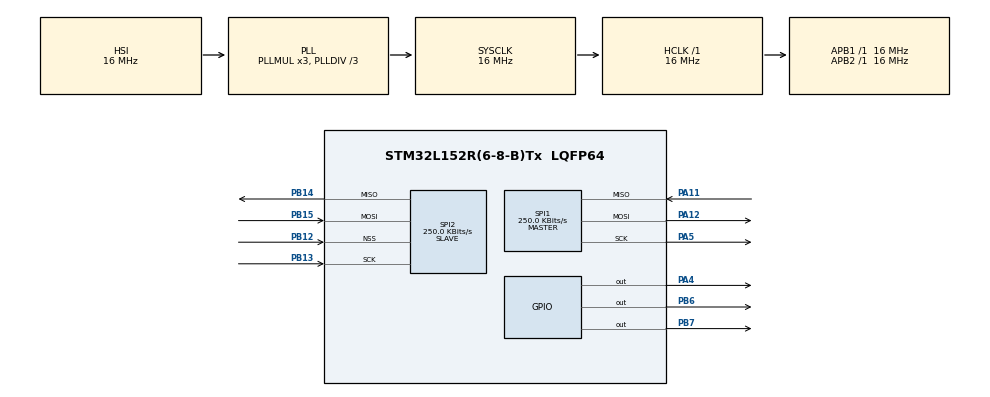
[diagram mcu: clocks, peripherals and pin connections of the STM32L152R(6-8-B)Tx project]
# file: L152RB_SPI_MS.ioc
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Dma.Request0=SPI2_RX
Dma.SPI2_RX.0.Direction=DMA_PERIPH_TO_MEMORY
Dma.SPI2_RX.0.Instance=DMA1_Channel4
Dma.SPI2_RX.0.MemDataAlignment=DMA_MDATAALIGN_BYTE
Dma.SPI2_RX.0.MemInc=DMA_MINC_ENABLE
Dma.SPI2_RX.0.Mode=DMA_CIRCULAR
Dma.SPI2_RX.0.PeriphDataAlignment=DMA_PDATAALIGN_BYTE
Dma.SPI2_RX.0.PeriphInc=DMA_PINC_DISABLE
Dma.SPI2_RX.0.Priority=DMA_PRIORITY_LOW
Mcu.Family=STM32L1
Mcu.Name=STM32L152R(6-8-B)Tx
Mcu.Package=LQFP64
NVIC.DMA1_Channel4_IRQn=true\:0\:0\:false\:false\:true\:false\:true
NVIC.PriorityGroup=NVIC_PRIORITYGROUP_4
NVIC.SPI1_IRQn=true\:0\:0\:false\:false\:true\:true\:true
NVIC.SPI2_IRQn=true\:0\:0\:false\:false\:true\:true\:true
PA11.Mode=Full_Duplex_Master
PA11.Signal=SPI1_MISO
PA12.Mode=Full_Duplex_Master
PA12.Signal=SPI1_MOSI
PA4.GPIO_Speed=GPIO_SPEED_FREQ_VERY_HIGH
PA4.PinState=GPIO_PIN_SET
PA4.Signal=GPIO_Output
PA5.Mode=Full_Duplex_Master
PA5.Signal=SPI1_SCK
PB12.Mode=NSS_Signal_Hard_Input
PB12.Signal=SPI2_NSS
PB13.Mode=Full_Duplex_Slave
PB13.Signal=SPI2_SCK
PB14.Mode=Full_Duplex_Slave
PB14.Signal=SPI2_MISO
PB15.Mode=Full_Duplex_Slave
PB15.Signal=SPI2_MOSI
PB6.PinState=GPIO_PIN_SET
PB6.Signal=GPIO_Output
PB7.PinState=GPIO_PIN_SET
PB7.Signal=GPIO_Output
ProjectManager.HeapSize=0x200
ProjectManager.StackSize=0x400
ProjectManager.TargetToolchain=STM32CubeIDE
RCC.AHBFreq_Value=16000000
RCC.APB1Freq_Value=16000000
RCC.APB1TimFreq_Value=16000000
RCC.APB2Freq_Value=16000000
RCC.APB2TimFreq_Value=16000000
RCC.HCLKFreq_Value=16000000
RCC.HSE_VALUE=24000000
RCC.HSI_VALUE=16000000
RCC.LSE_VALUE=32768
RCC.MSI_VALUE=2097000
RCC.PLLDIV=RCC_PLL_DIV3
RCC.SYSCLKFreq_VALUE=16000000
RCC.SYSCLKSource=RCC_SYSCLKSOURCE_PLLCLK
RCC.VCOOutputFreq_Value=48000000
SPI1.BaudRatePrescaler=SPI_BAUDRATEPRESCALER_64
SPI1.CalculateBaudRate=250.0 KBits/s
SPI1.Direction=SPI_DIRECTION_2LINES
SPI1.Mode=SPI_MODE_MASTER
SPI1.VirtualType=VM_MASTER
SPI2.BaudRatePrescaler=SPI_BAUDRATEPRESCALER_64
SPI2.CalculateBaudRate=250.0 KBits/s
SPI2.Direction=SPI_DIRECTION_2LINES
SPI2.Mode=SPI_MODE_SLAVE
SPI2.VirtualNSS=VM_NSSHARD
SPI2.VirtualType=VM_SLAVE
board=custom

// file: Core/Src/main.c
/* USER CODE BEGIN Header */
/**
  ******************************************************************************
  * @file           : main.c
  * @brief          : Main program body
  ******************************************************************************
  * @attention
  *
  * <h2><center>&copy; Copyright (c) 2020 STMicroelectronics.
  * All rights reserved.</center></h2>
  *
  * This software component is licensed by ST under BSD 3-Clause license,
  * the "License"; You may not use this file except in compliance with the
  * License. You may obtain a copy of the License at:
  *                        opensource.org/licenses/BSD-3-Clause
  *
  ******************************************************************************
  */
/* USER CODE END Header */
#include "main.h"

/* USER CODE BEGIN PTD */
#define spi_enable  	HAL_GPIO_WritePin(GPIOA, GPIO_PIN_4, GPIO_PIN_RESET);
#define spi_disable 	HAL_GPIO_WritePin(GPIOA, GPIO_PIN_4, GPIO_PIN_SET);
/* USER CODE END PTD */

SPI_HandleTypeDef hspi1;
SPI_HandleTypeDef hspi2;
DMA_HandleTypeDef hdma_spi2_rx;

/* USER CODE BEGIN PV */
uint8_t send_data = 32;
uint8_t receive_data = 0;
/* USER CODE END PV */

void SystemClock_Config(void);
static void MX_GPIO_Init(void);
static void MX_DMA_Init(void);
static void MX_SPI1_Init(void);
static void MX_SPI2_Init(void);

int main(void)
{

  /* MCU Configuration--------------------------------------------------------*/

  /* Reset of all peripherals, Initializes the Flash interface and the Systick. */
  HAL_Init();

  /* Configure the system clock */
  SystemClock_Config();

  /* Initialize all configured peripherals */
  MX_GPIO_Init();
  MX_DMA_Init();
  MX_SPI1_Init();
  MX_SPI2_Init();
  //spi_disable;
  //HAL_SPI_Receive_DMA(&hspi2, &receive_data, 1);
  /* Infinite loop */
  /* USER CODE BEGIN WHILE */
  while (1)
  {
	  spi_enable;
	  HAL_SPI_Transmit_IT(&hspi1, &send_data, 1);
	  spi_disable;
	  send_data++;
	  HAL_Delay(1000);
  }
  /* USER CODE END 3 */
}

void HAL_SPI_TxCpltCallback(SPI_HandleTypeDef *hspi)
{
	if(hspi->Instance == hspi1.Instance)
	{
		HAL_GPIO_TogglePin(GPIOB, GPIO_PIN_6);
	}
}

void HAL_SPI_RxCpltCallback(SPI_HandleTypeDef *hspi)
{
	if(hspi->Instance == hspi2.Instance)
	{
		HAL_GPIO_TogglePin(GPIOB, GPIO_PIN_7);
		//spi_disable;
	}
}
void SystemClock_Config(void)
{
  RCC_OscInitTypeDef RCC_OscInitStruct = {0};
  RCC_ClkInitTypeDef RCC_ClkInitStruct = {0};

  /** Configure the main internal regulator output voltage
  */
  __HAL_PWR_VOLTAGESCALING_CONFIG(PWR_REGULATOR_VOLTAGE_SCALE1);
  /** Initializes the RCC Oscillators according to the specified parameters
  * in the RCC_OscInitTypeDef structure.
  */
  RCC_OscInitStruct.OscillatorType = RCC_OSCILLATORTYPE_HSI;
  RCC_OscInitStruct.HSIState = RCC_HSI_ON;
  RCC_OscInitStruct.HSICalibrationValue = RCC_HSICALIBRATION_DEFAULT;
  RCC_OscInitStruct.PLL.PLLState = RCC_PLL_ON;
  RCC_OscInitStruct.PLL.PLLSource = RCC_PLLSOURCE_HSI;
  RCC_OscInitStruct.PLL.PLLMUL = RCC_PLL_MUL3;
  RCC_OscInitStruct.PLL.PLLDIV = RCC_PLL_DIV3;
  if (HAL_RCC_OscConfig(&RCC_OscInitStruct) != HAL_OK)
  {
    Error_Handler();
  }
  /** Initializes the CPU, AHB and APB buses clocks
  */
  RCC_ClkInitStruct.ClockType = RCC_CLOCKTYPE_HCLK|RCC_CLOCKTYPE_SYSCLK
                              |RCC_CLOCKTYPE_PCLK1|RCC_CLOCKTYPE_PCLK2;
  RCC_ClkInitStruct.SYSCLKSource = RCC_SYSCLKSOURCE_PLLCLK;
  RCC_ClkInitStruct.AHBCLKDivider = RCC_SYSCLK_DIV1;
  RCC_ClkInitStruct.APB1CLKDivider = RCC_HCLK_DIV1;
  RCC_ClkInitStruct.APB2CLKDivider = RCC_HCLK_DIV1;

  if (HAL_RCC_ClockConfig(&RCC_ClkInitStruct, FLASH_LATENCY_0) != HAL_OK)
  {
    Error_Handler();
  }
}

static void MX_SPI1_Init(void)
{

  /* SPI1 parameter configuration*/
  hspi1.Instance = SPI1;
  hspi1.Init.Mode = SPI_MODE_MASTER;
  hspi1.Init.Direction = SPI_DIRECTION_2LINES;
  hspi1.Init.DataSize = SPI_DATASIZE_8BIT;
  hspi1.Init.CLKPolarity = SPI_POLARITY_LOW;
  hspi1.Init.CLKPhase = SPI_PHASE_1EDGE;
  hspi1.Init.NSS = SPI_NSS_SOFT;
  hspi1.Init.BaudRatePrescaler = SPI_BAUDRATEPRESCALER_64;
  hspi1.Init.FirstBit = SPI_FIRSTBIT_MSB;
  hspi1.Init.TIMode = SPI_TIMODE_DISABLE;
  hspi1.Init.CRCCalculation = SPI_CRCCALCULATION_DISABLE;
  hspi1.Init.CRCPolynomial = 10;
  if (HAL_SPI_Init(&hspi1) != HAL_OK)
  {
    Error_Handler();
  }

}

static void MX_SPI2_Init(void)
{

  /* SPI2 parameter configuration*/
  hspi2.Instance = SPI2;
  hspi2.Init.Mode = SPI_MODE_SLAVE;
  hspi2.Init.Direction = SPI_DIRECTION_2LINES;
  hspi2.Init.DataSize = SPI_DATASIZE_8BIT;
  hspi2.Init.CLKPolarity = SPI_POLARITY_LOW;
  hspi2.Init.CLKPhase = SPI_PHASE_1EDGE;
  hspi2.Init.NSS = SPI_NSS_HARD_INPUT;
  hspi2.Init.BaudRatePrescaler = SPI_BAUDRATEPRESCALER_64;
  hspi2.Init.FirstBit = SPI_FIRSTBIT_MSB;
  hspi2.Init.TIMode = SPI_TIMODE_DISABLE;
  hspi2.Init.CRCCalculation = SPI_CRCCALCULATION_DISABLE;
  hspi2.Init.CRCPolynomial = 10;
  if (HAL_SPI_Init(&hspi2) != HAL_OK)
  {
    Error_Handler();
  }

}

static void MX_DMA_Init(void)
{

  /* DMA controller clock enable */
  __HAL_RCC_DMA1_CLK_ENABLE();

  /* DMA interrupt init */
  /* DMA1_Channel4_IRQn interrupt configuration */
  HAL_NVIC_SetPriority(DMA1_Channel4_IRQn, 0, 0);
  HAL_NVIC_EnableIRQ(DMA1_Channel4_IRQn);

}

static void MX_GPIO_Init(void)
{
  GPIO_InitTypeDef GPIO_InitStruct = {0};

  /* GPIO Ports Clock Enable */
  __HAL_RCC_GPIOA_CLK_ENABLE();
  __HAL_RCC_GPIOB_CLK_ENABLE();

  /*Configure GPIO pin Output Level */
  HAL_GPIO_WritePin(GPIOA, GPIO_PIN_4, GPIO_PIN_SET);

  /*Configure GPIO pin Output Level */
  HAL_GPIO_WritePin(GPIOB, GPIO_PIN_6|GPIO_PIN_7, GPIO_PIN_SET);

  /*Configure GPIO pin : PA4 */
  GPIO_InitStruct.Pin = GPIO_PIN_4;
  GPIO_InitStruct.Mode = GPIO_MODE_OUTPUT_PP;
  GPIO_InitStruct.Pull = GPIO_NOPULL;
  GPIO_InitStruct.Speed = GPIO_SPEED_FREQ_VERY_HIGH;
  HAL_GPIO_Init(GPIOA, &GPIO_InitStruct);

  /*Configure GPIO pins : PB6 PB7 */
  GPIO_InitStruct.Pin = GPIO_PIN_6|GPIO_PIN_7;
  GPIO_InitStruct.Mode = GPIO_MODE_OUTPUT_PP;
  GPIO_InitStruct.Pull = GPIO_NOPULL;
  GPIO_InitStruct.Speed = GPIO_SPEED_FREQ_LOW;
  HAL_GPIO_Init(GPIOB, &GPIO_InitStruct);

}

void Error_Handler(void)
{
}

/************************ (C) COPYRIGHT STMicroelectronics *****END OF FILE****/
